# STM32N657xx register map
File version: 1.0
Registers are 32-bit, read-write, reset 0x0 unless marked. A register's access mark holds for its fields unless they carry their own. Offsets are from the block's base; [hi:lo] are bit positions; {n}, {i} and the like mark numbered series.

## SAES — SAES Processor
Base 0x44021000
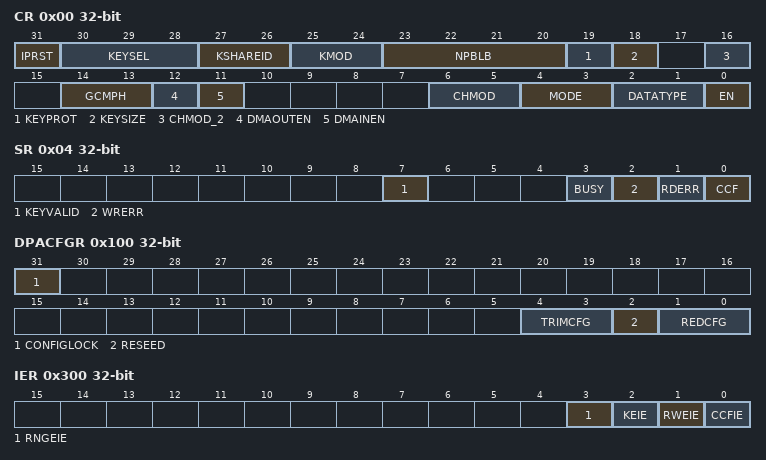
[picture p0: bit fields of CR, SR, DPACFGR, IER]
0x00 CR — SAES control register
  [31] IPRST — SAES IP software reset
  [30:28] KEYSEL — Key Selection
  [27:26] KSHAREID — Key Shared ID
  [25:24] KMOD — Key mode selection
  [23:20] NPBLB — Number of padding bytes in last block
  [19] KEYPROT — Key protection
  [18] KEYSIZE — Key size selection
  [16] CHMOD_2 — SAES Chaining Mode
  [14:13] GCMPH — GCM or CCM phase selection
  [12] DMAOUTEN — Enable data output phase DMA management
  [11] DMAINEN — Enable data input phase DMA management
  [6:5] CHMOD — SAES Chaining Mode
  [4:3] MODE — SAES Mode Of Operation
  [2:1] DATATYPE — Data type selection
  [0] EN — SAES Enable
0x04 SR — SAES status register
  [7] KEYVALID — Key valid Flag
  [3] BUSY — Busy Flag
  [2] WRERR — Write Error Flag
  [1] RDERR — Read Error Flag
  [0] CCF — Computation Complete Flag
0x08 DINR — SAES data input register
  [31:0] DINR — SAES Data Input Register
0x0C DOUTR — SAES data output register
  [31:0] DOUTR — SAES Data Output Register
{0x10+4i} KEYR{i} (i=0..3) — SAES key register {i}
  [31:0] KEYR{i} — SAES cryptographic key, bits [{32i+31}:{32i}]
{0x20+4i} IVR{i} (i=0..3) — SAES initialization vector register {i}
  [31:0] IVR{i} — SAES initialization vector input, bits [{32i+31}:{32i}]
{0x20+4i} KEYR{i} (i=4..7) — SAES key register {i}
  [31:0] KEYR{i} — SAES cryptographic key, bits [127:96]
0x100 DPACFGR — SAES DPA configuration register
  [31] CONFIGLOCK — DPA configuration lock
  [4:3] TRIMCFG — Clock trimming
  [2] RESEED — Automatic reseed enable
  [1:0] REDCFG — Redundancy configuration
0x300 IER — SAES Interrupt Enable Register
  [3] RNGEIE — RNG error interrupt enable
  [2] KEIE — Key error interrupt enable
  [1] RWEIE — Read or write error Interrupt Enable
  [0] CCFIE — Computation complete flag interrupt enable
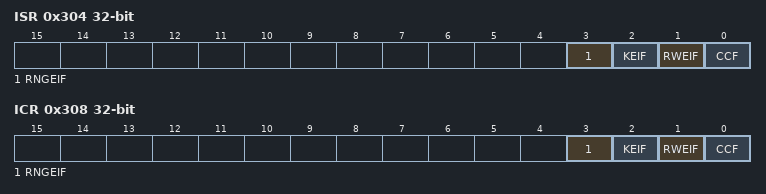
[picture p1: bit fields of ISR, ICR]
0x304 ISR — SAES Interrupt Status Register
  [3] RNGEIF — RNG error interrupt flag
  [2] KEIF — Key error interrupt flag
  [1] RWEIF — Read or write error Interrupt flag
  [0] CCF — Computation complete flag
0x308 ICR — SAES Interrupt Clear Register
  [3] RNGEIF — RNG error interrupt flag clear
  [2] KEIF — Key error interrupt flag clear
  [1] RWEIF — Read or write error Interrupt flag clear
  [0] CCF — Computation complete flag clear

## PKA
Base 0x44022000
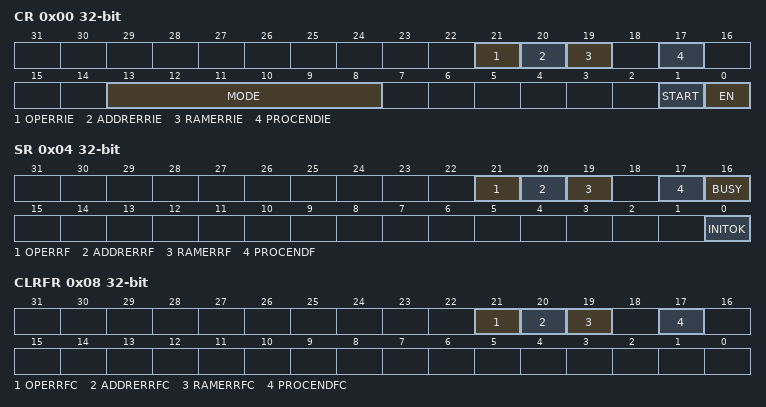
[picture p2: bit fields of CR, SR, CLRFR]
0x00 CR — PKA control register
  [21] OPERRIE — Operation Error interrupt enable
  [20] ADDRERRIE — Address error interrupt enable
  [19] RAMERRIE — RAM error interrupt enable
  [17] PROCENDIE — End of operation interrupt enable
  [13:8] MODE — MODE[5:0] PKA operation code
  [1] START — Start operation
  [0] EN — PKA enable
0x04 SR — PKA status register
  [21] OPERRF — PKA operation Error flag
  [20] ADDRERRF — Address error flag
  [19] RAMERRF — PKA RAM error flag
  [17] PROCENDF — PKA end of operation flag
  [16] BUSY — PKA operation is in progress
  [0] INITOK — PKA initialisation flag
0x08 CLRFR — PKA clear flag register
  [21] OPERRFC — Clear PKA operation Error flag
  [20] ADDRERRFC — Clear address error flag
  [19] RAMERRFC — Clear PKA RAM error flag
  [17] PROCENDFC — Clear PKA end of operation flag
{0x400+4i} RAM[{i}] (i=0..1333)

## RIFSC
Base 0x44024000
0x00 RISC_CR — RIFSC RISC slave configuration register x
  [0] GLOCK — Global lock
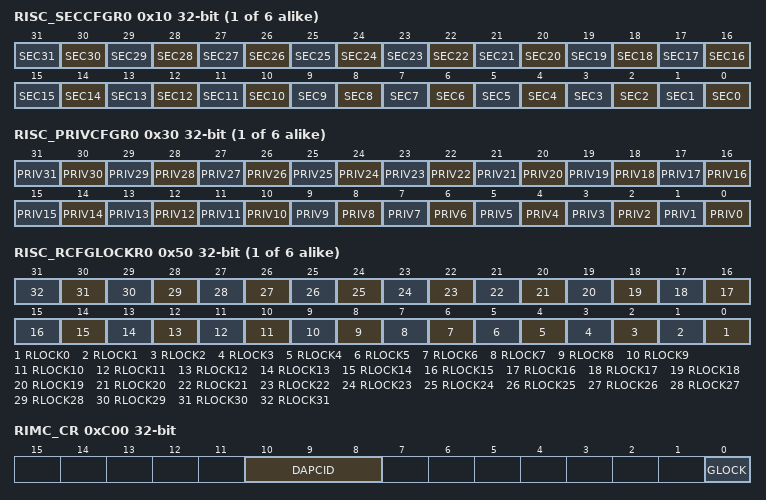
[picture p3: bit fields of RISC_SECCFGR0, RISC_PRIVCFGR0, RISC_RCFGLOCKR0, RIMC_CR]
{0x10+4i} RISC_SECCFGR{i} (i=0..5) — RIFSC RISC slave security configuration register x
  [n] SEC{n} (n=0..31) — Security configuration for peripheral {n}
{0x30+4i} RISC_PRIVCFGR{i} (i=0..5) — RIFSC RISFC slave privileged register x
  [n] PRIV{n} (n=0..31) — privileged-only access permission for peripheral {n}
{0x50+4i} RISC_RCFGLOCKR{i} (i=0..5) — RIFSC RISC slave resource configuration lock register x
  [n] RLOCK{n} (n=0..31) — Resource lock for peripheral {n}
0xC00 RIMC_CR — RIFSC RIMC master configuration register
  [10:8] DAPCID — Debug access port compartment ID
  [0] GLOCK — Global lock
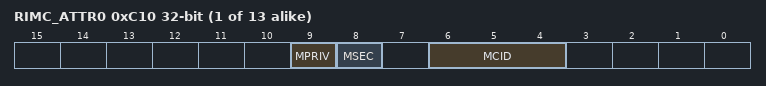
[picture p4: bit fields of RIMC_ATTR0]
{0xC10+4i} RIMC_ATTR{i} (i=0..12) — RIFSC RIMC master attribute register x
  [9] MPRIV — Master privileged
  [8] MSEC — Master secure
  [6:4] MCID — Master CID
{0xFB0+4i} PPSR{i} (i=0..5) — RIFSC peripheral protection status register x
